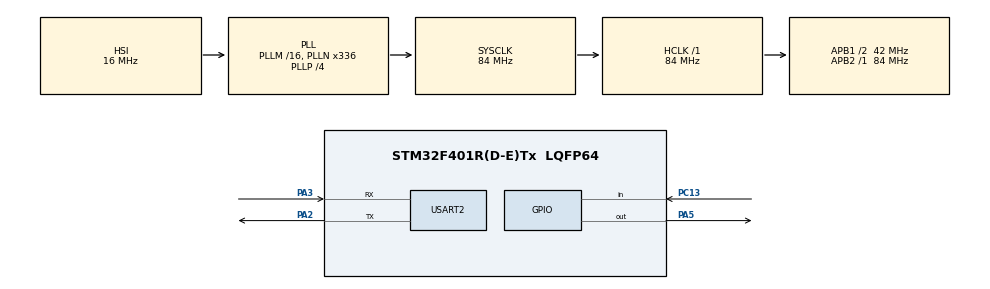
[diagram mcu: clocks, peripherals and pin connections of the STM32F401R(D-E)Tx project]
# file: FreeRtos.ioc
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FREERTOS.Mutexes01=UartMutex,Dynamic,NULL
FREERTOS.Tasks01=defaultTask,0,128,Thread1,Default,NULL,Dynamic,NULL,NULL;myTask02,-3,128,Thread2,Default,NULL,Dynamic,NULL,NULL
Mcu.Family=STM32F4
Mcu.Name=STM32F401R(D-E)Tx
Mcu.Package=LQFP64
NVIC.PriorityGroup=NVIC_PRIORITYGROUP_4
NVIC.TIM3_IRQn=true\:0\:0\:false\:false\:true\:false\:false
NVIC.TimeBase=TIM3_IRQn
NVIC.TimeBaseIP=TIM3
PA2.Mode=Asynchronous
PA2.Signal=USART2_TX
PA3.Mode=Asynchronous
PA3.Signal=USART2_RX
PA5.Signal=GPIO_Output
PC13-ANTI_TAMP.Signal=GPIO_Input
ProjectManager.HeapSize=0x200
ProjectManager.StackSize=0x400
ProjectManager.TargetToolchain=MDK-ARM V5
RCC.48MHZClocksFreq_Value=48000000
RCC.AHBFreq_Value=84000000
RCC.APB1CLKDivider=RCC_HCLK_DIV2
RCC.APB1Freq_Value=42000000
RCC.APB1TimFreq_Value=84000000
RCC.APB2Freq_Value=84000000
RCC.APB2TimFreq_Value=84000000
RCC.CortexFreq_Value=84000000
RCC.HCLKFreq_Value=84000000
RCC.HSE_VALUE=8000000
RCC.HSI_VALUE=16000000
RCC.PLLN=336
RCC.PLLP=RCC_PLLP_DIV4
RCC.PLLQ=7
RCC.SYSCLKFreq_VALUE=84000000
RCC.SYSCLKSource=RCC_SYSCLKSOURCE_PLLCLK
RCC.VCOOutputFreq_Value=336000000
USART2.VirtualMode=VM_ASYNC
VP_FREERTOS_VS_ENABLE.Mode=Enabled
VP_SYS_VS_tim3.Mode=TIM3
board=NUCLEO-F401RE

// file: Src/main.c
/**
  ******************************************************************************
  * @file           : main.c
  * @brief          : Main program body
  ******************************************************************************
  * This notice applies to any and all portions of this file
  * that are not between comment pairs USER CODE BEGIN and
  * USER CODE END. Other portions of this file, whether
  * inserted by the user or by software development tools
  * are owned by their respective copyright owners.
  *
  * Copyright (c) 2018 STMicroelectronics International N.V.
  * All rights reserved.
  *
  * Redistribution and use in source and binary forms, with or without
  * modification, are permitted, provided that the following conditions are met:
  *
  * 1. Redistribution of source code must retain the above copyright notice,
  *    this list of conditions and the following disclaimer.
  * 2. Redistributions in binary form must reproduce the above copyright notice,
  *    this list of conditions and the following disclaimer in the documentation
  *    and/or other materials provided with the distribution.
  * 3. Neither the name of STMicroelectronics nor the names of other
  *    contributors to this software may be used to endorse or promote products
  *    derived from this software without specific written permission.
  * 4. This software, including modifications and/or derivative works of this
  *    software, must execute solely and exclusively on microcontroller or
  *    microprocessor devices manufactured by or for STMicroelectronics.
  * 5. Redistribution and use of this software other than as permitted under
  *    this license is void and will automatically terminate your rights under
  *    this license.
  *
  * THIS SOFTWARE IS PROVIDED BY STMICROELECTRONICS AND CONTRIBUTORS "AS IS"
  * AND ANY EXPRESS, IMPLIED OR STATUTORY WARRANTIES, INCLUDING, BUT NOT
  * LIMITED TO, THE IMPLIED WARRANTIES OF MERCHANTABILITY, FITNESS FOR A
  * PARTICULAR PURPOSE AND NON-INFRINGEMENT OF THIRD PARTY INTELLECTUAL PROPERTY
  * RIGHTS ARE DISCLAIMED TO THE FULLEST EXTENT PERMITTED BY LAW. IN NO EVENT
  * SHALL STMICROELECTRONICS OR CONTRIBUTORS BE LIABLE FOR ANY DIRECT, INDIRECT,
  * INCIDENTAL, SPECIAL, EXEMPLARY, OR CONSEQUENTIAL DAMAGES (INCLUDING, BUT NOT
  * LIMITED TO, PROCUREMENT OF SUBSTITUTE GOODS OR SERVICES; LOSS OF USE, DATA,
  * OR PROFITS; OR BUSINESS INTERRUPTION) HOWEVER CAUSED AND ON ANY THEORY OF
  * LIABILITY, WHETHER IN CONTRACT, STRICT LIABILITY, OR TORT (INCLUDING
  * NEGLIGENCE OR OTHERWISE) ARISING IN ANY WAY OUT OF THE USE OF THIS SOFTWARE,
  * EVEN IF ADVISED OF THE POSSIBILITY OF SUCH DAMAGE.
  *
  ******************************************************************************
  */
#include "main.h"
#include "stm32f4xx_hal.h"
#include "cmsis_os.h"

UART_HandleTypeDef huart2;

osThreadId defaultTaskHandle;
osThreadId myTask02Handle;
osMutexId UartMutexHandle;

/* USER CODE BEGIN PV */
/* Private variables ---------------------------------------------------------*/

/* USER CODE END PV */

void SystemClock_Config(void);
static void MX_GPIO_Init(void);
static void MX_USART2_UART_Init(void);
void Thread1(void const * argument);
void Thread2(void const * argument);

/* USER CODE BEGIN PFP */
/* Private function prototypes -----------------------------------------------*/

/* USER CODE END PFP */

int main(void)
{

  /* MCU Configuration----------------------------------------------------------*/

  /* Reset of all peripherals, Initializes the Flash interface and the Systick. */
  HAL_Init();

  /* Configure the system clock */
  SystemClock_Config();

  /* Initialize all configured peripherals */
  MX_GPIO_Init();
  MX_USART2_UART_Init();

  /* Create the mutex(es) */
  /* definition and creation of UartMutex */
  osMutexDef(UartMutex);
  UartMutexHandle = osMutexCreate(osMutex(UartMutex));

  /* Create the thread(s) */
  /* definition and creation of defaultTask */
  osThreadDef(defaultTask, Thread1, osPriorityNormal, 0, 128);
  defaultTaskHandle = osThreadCreate(osThread(defaultTask), NULL);

  /* definition and creation of myTask02 */
  osThreadDef(myTask02, Thread2, osPriorityIdle, 0, 128);
  myTask02Handle = osThreadCreate(osThread(myTask02), NULL);

  /* Start scheduler */
  osKernelStart();

  /* We should never get here as control is now taken by the scheduler */

  /* Infinite loop */
  while (1)
  {

  }

}

void SystemClock_Config(void)
{

  RCC_OscInitTypeDef RCC_OscInitStruct;
  RCC_ClkInitTypeDef RCC_ClkInitStruct;

    /**Configure the main internal regulator output voltage
    */
  __HAL_RCC_PWR_CLK_ENABLE();

  __HAL_PWR_VOLTAGESCALING_CONFIG(PWR_REGULATOR_VOLTAGE_SCALE2);

    /**Initializes the CPU, AHB and APB busses clocks
    */
  RCC_OscInitStruct.OscillatorType = RCC_OSCILLATORTYPE_HSI;
  RCC_OscInitStruct.HSIState = RCC_HSI_ON;
  RCC_OscInitStruct.HSICalibrationValue = 16;
  RCC_OscInitStruct.PLL.PLLState = RCC_PLL_ON;
  RCC_OscInitStruct.PLL.PLLSource = RCC_PLLSOURCE_HSI;
  RCC_OscInitStruct.PLL.PLLM = 16;
  RCC_OscInitStruct.PLL.PLLN = 336;
  RCC_OscInitStruct.PLL.PLLP = RCC_PLLP_DIV4;
  RCC_OscInitStruct.PLL.PLLQ = 7;
  if (HAL_RCC_OscConfig(&RCC_OscInitStruct) != HAL_OK)
  {
    _Error_Handler(__FILE__, __LINE__);
  }

    /**Initializes the CPU, AHB and APB busses clocks
    */
  RCC_ClkInitStruct.ClockType = RCC_CLOCKTYPE_HCLK|RCC_CLOCKTYPE_SYSCLK
                              |RCC_CLOCKTYPE_PCLK1|RCC_CLOCKTYPE_PCLK2;
  RCC_ClkInitStruct.SYSCLKSource = RCC_SYSCLKSOURCE_PLLCLK;
  RCC_ClkInitStruct.AHBCLKDivider = RCC_SYSCLK_DIV1;
  RCC_ClkInitStruct.APB1CLKDivider = RCC_HCLK_DIV2;
  RCC_ClkInitStruct.APB2CLKDivider = RCC_HCLK_DIV1;

  if (HAL_RCC_ClockConfig(&RCC_ClkInitStruct, FLASH_LATENCY_2) != HAL_OK)
  {
    _Error_Handler(__FILE__, __LINE__);
  }

    /**Configure the Systick interrupt time
    */
  HAL_SYSTICK_Config(HAL_RCC_GetHCLKFreq()/1000);

    /**Configure the Systick
    */
  HAL_SYSTICK_CLKSourceConfig(SYSTICK_CLKSOURCE_HCLK);

  /* SysTick_IRQn interrupt configuration */
  HAL_NVIC_SetPriority(SysTick_IRQn, 15, 0);
}

/* USART2 init function */
static void MX_USART2_UART_Init(void)
{

  huart2.Instance = USART2;
  huart2.Init.BaudRate = 115200;
  huart2.Init.WordLength = UART_WORDLENGTH_8B;
  huart2.Init.StopBits = UART_STOPBITS_1;
  huart2.Init.Parity = UART_PARITY_NONE;
  huart2.Init.Mode = UART_MODE_TX_RX;
  huart2.Init.HwFlowCtl = UART_HWCONTROL_NONE;
  huart2.Init.OverSampling = UART_OVERSAMPLING_16;
  if (HAL_UART_Init(&huart2) != HAL_OK)
  {
    _Error_Handler(__FILE__, __LINE__);
  }

}

/** Configure pins as
        * Analog
        * Input
        * Output
        * EVENT_OUT
        * EXTI
*/
static void MX_GPIO_Init(void)
{

  GPIO_InitTypeDef GPIO_InitStruct;

  /* GPIO Ports Clock Enable */
  __HAL_RCC_GPIOC_CLK_ENABLE();
  __HAL_RCC_GPIOA_CLK_ENABLE();

  /*Configure GPIO pin Output Level */
  HAL_GPIO_WritePin(GPIOA, GPIO_PIN_5, GPIO_PIN_RESET);

  /*Configure GPIO pin : PC13 */
  GPIO_InitStruct.Pin = GPIO_PIN_13;
  GPIO_InitStruct.Mode = GPIO_MODE_INPUT;
  GPIO_InitStruct.Pull = GPIO_NOPULL;
  HAL_GPIO_Init(GPIOC, &GPIO_InitStruct);

  /*Configure GPIO pin : PA5 */
  GPIO_InitStruct.Pin = GPIO_PIN_5;
  GPIO_InitStruct.Mode = GPIO_MODE_OUTPUT_PP;
  GPIO_InitStruct.Pull = GPIO_NOPULL;
  GPIO_InitStruct.Speed = GPIO_SPEED_FREQ_LOW;
  HAL_GPIO_Init(GPIOA, &GPIO_InitStruct);

}

/* Thread1 function */
void Thread1(void const * argument)
{

  /* USER CODE BEGIN 5 */
	uint8_t TxData[20] = "Hello From Thread1\r\n";

  /* Infinite loop */
  for(;;)
  {
		HAL_GPIO_TogglePin(GPIOA, GPIO_PIN_5);
		xSemaphoreTake(UartMutexHandle, portMAX_DELAY);
		HAL_UART_Transmit(&huart2,TxData,20,5);
		xSemaphoreGive(UartMutexHandle);
    osDelay(1000);
	}

  /* USER CODE END 5 */
}

/* Thread2 function */
void Thread2(void const * argument)
{
  /* USER CODE BEGIN Thread2 */
	uint8_t TxData[20] = "Hello From Thread2\r\n";
  /* Infinite loop */
  for(;;)
  {
		if(HAL_GPIO_ReadPin(GPIOC, GPIO_PIN_13)== GPIO_PIN_RESET)
		{
			xSemaphoreTake(UartMutexHandle, portMAX_DELAY);
			HAL_UART_Transmit(&huart2,TxData,20,5);
			xSemaphoreGive(UartMutexHandle);
     osDelay(1000);
		}
  }
  /* USER CODE END Thread2 */
}

void HAL_TIM_PeriodElapsedCallback(TIM_HandleTypeDef *htim)
{
  if (htim->Instance == TIM3) {
    HAL_IncTick();
  }
}

void _Error_Handler(char *file, int line)
{
  while(1)
  {
  }
}

/************************ (C) COPYRIGHT STMicroelectronics *****END OF FILE****/
